# haltium_cellcore register map
Vendor: Nordic Semiconductor; Series: nRFHaltium; File version: 1
CPU: CM33 r0p4, little endian, MPU, FPU, 3 interrupt priority bits, 480 interrupts
Registers are 32-bit, read-write, reset 0x0 unless marked. A register's access mark holds for its fields unless they carry their own. Offsets are from the block's base; [hi:lo] are bit positions; lines under a group give offsets from that group; {n}, {i} and the like mark numbered series; 'fields as' and 'values as' point back to an identical list.

## AXI_S — AXI AXI Core
Base 0x54004000
0x400 CORE group — Unspecified
  0x00 AXIVERSIONIDREG reset 0x3430332A — AXI Component Version ID register. This register represents the AXI_component version.
    [31:0] AXIVERIDFIELDS ro — AXI Version ID Number. ASCII value of each number in component version followed by *. For example, 33_30_30_2A represents the version 3.00*.
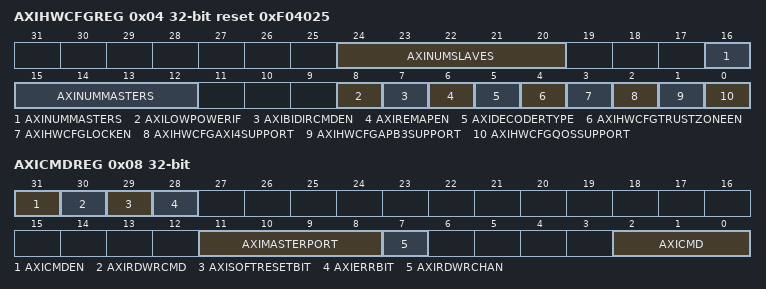
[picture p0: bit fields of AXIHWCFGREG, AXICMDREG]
  0x04 AXIHWCFGREG reset 0xF04025 — AXI Hardware Configuration Register. This register provides the configuration details of the AXI.
    [24:20] AXINUMSLAVES ro — Number of AXI Slaves.
    [16:12] AXINUMMASTERS ro — Number of AXI masters.
    [8] AXILOWPOWERIF ro — Include/exclude low-power interface.
      0=REMAPNOTSUPPORTED (Unspecified); 1=REMAPSUPPORTED (Unspecified)
    [7] AXIBIDIRCMDEN ro — Support for Enable Bi-directional Command.
      values as AXILOWPOWERIF
    [6] AXIREMAPEN ro — Support for Enable Remap mode.
      values as AXILOWPOWERIF
    [5] AXIDECODERTYPE ro — Use of External/Internal Decoder.
      0=INTDECODER (Unspecified); 1=EXTDECODER (Unspecified)
    [4] AXIHWCFGTRUSTZONEEN ro — Support for Enable Trust Zone.
      0=TZENNOTSUPPORTED (Unspecified); 1=TZENSUPPORTED (Unspecified)
    [3] AXIHWCFGLOCKEN ro — Support for Enable Lock transactions.
      0=LOCKENNOTSUPPORTED (Unspecified); 1=LOCKENSUPPORTED (Unspecified)
    [2] AXIHWCFGAXI4SUPPORT ro — Support for AXI4 features.
      0=AXI4NOTSUPPORTED (Unspecified); 1=AXI4SUPPORTED (Unspecified)
    [1] AXIHWCFGAPB3SUPPORT ro — Has APB3 support.
      0=APB3NOTSUPPORTED (Unspecified); 1=APB3SUPPORTED (Unspecified)
    [0] AXIHWCFGQOSSUPPORT ro — QOS Support.
      0=QOSDISABLED (Unspecified); 1=QOSENABLED (Unspecified)
  0x08 AXICMDREG — AXI Command Enable Register.
    [31] AXICMDEN — Command enable. This bit must be set to 1 to execute the command in this register. In case the bit is not set to 1, the command in the register will not be executed. Once set to 1, this bit can be reset to 0 only by the interconnect logic after performing the command in the register. In case, APB master tries to write another command in the register that will be ignored without any error message. Similarly, APB master will not be allowed to clear this bit. The access type is R_W0 (Read and Write on 0).
      0=ACCEPTCMD (The command register is ready to accept new commands. The data register holds the data of the last successful transaction depending on whether it was for a read or write.); 1=EXECCMD (The command in the register is valid and it is not yet completed by the interconnect. The command and data registers are locked for any updates till this bit is reset to 0. Any write to this bit by APB master when it is already set to 1 will be ignored without any error.)
    [30] AXIRDWRCMD — Read/write bit.This bit decodes if the type of command for QoS internal registers offset mentioned in CMD [2:0]. It is valid only if Command enable bit is set to 1.
      0=RDCMD (Read command); 1=WRCMD (Write command)
    [29] AXISOFTRESETBIT — Internal Register reset. When this bit is set to 1 by the APB master, it resets all registers in the interconnect to their reset values.
      0=ACTIVEINTREG (Unspecified); 1=RESETINTREG (Unspecified)
    [28] AXIERRBIT ro — Error Bit. This bit is a read-only bit as it is set to 1 only by the interconnect in case of error scenarios. It is valid only once command enable is reset to 0 by the interconnect. It will be cleared to 0 on next write to the command register by APB master.
      0=ERRBITNOTSET (Unspecified); 1=ERRBITSET (Unspecified)
    [11:8] AXIMASTERPORT — Master Port ID. Identifies the master port for which command (bit[2:0]) is configured.
      {v}=MASTERPORT{v+1} (v=0..15)
    [7] AXIRDWRCHAN — Read Address Channel /Write Address Channel. Identifies that the command is for read address channel or write address channel of the master port (bit[11:8]).
      0=CMDWRITEADDRCH (the command is for read address channel); 1=CMDREADADDRCH (the command is for write address channel)
    [2:0] AXICMD — Command selection for internal registers.
      0=BURSTREGEN (Burstiness Regulator Enable); 1=PEAKRATEXCTRATE; 2=QOSVALUE; 3=SLVREADY (Slave Ready)
  0x0C AXIDATAREG — AXI Data Register. This register is programmed through the APB interface.
    [31:0] AXIDATA — Data to be written into the QoS internal register
